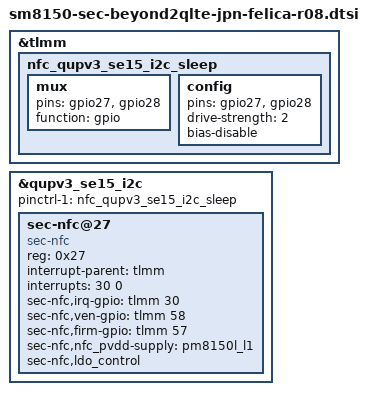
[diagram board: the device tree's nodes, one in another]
/*
 * This program is free software; you can redistribute it and/or modify
 * it under the terms of the GNU General Public License version 2 and
 * only version 2 as published by the Free Software Foundation.
 *
 * This program is distributed in the hope that it will be useful,
 * but WITHOUT ANY WARRANTY; without even the implied warranty of
 * MERCHANTABILITY or FITNESS FOR A PARTICULAR PURPOSE.  See the
 * GNU General Public License for more details.
 */
&tlmm {
	nfc_qupv3_se15_i2c_sleep: nfc_qupv3_se15_i2c_sleep {
		mux {
			pins = "gpio27", "gpio28";
			function = "gpio";
		};

		config {
			pins = "gpio27", "gpio28";
			drive-strength = <2>;
			bias-disable;
		};
	};
};

&qupv3_se15_i2c {
	status = "ok";
	pinctrl-1 = <&nfc_qupv3_se15_i2c_sleep>;
	/delete-node/ pn547@2B;
	sec-nfc@27 {
		compatible = "sec-nfc";
		reg = <0x27>;
		interrupt-parent = <&tlmm>;
		interrupts= <30 0>;
		sec-nfc,irq-gpio = <&tlmm 30 0>;
		sec-nfc,ven-gpio = <&tlmm 58 0>;
		sec-nfc,firm-gpio = <&tlmm 57 0>;
		/*sec-nfc,clk_req-gpio = <&pm8998_gpios 21 0x00>;*/
		/*pn547,pwr_req =  <&expander_gpios 1 0>;*/
		sec-nfc,nfc_pvdd-supply = <&pm8150l_l1>;
		sec-nfc,ldo_control;
	};
};
